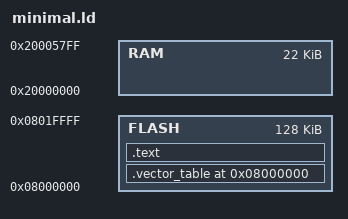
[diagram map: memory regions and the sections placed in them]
MEMORY
{
  FLASH : ORIGIN = 0x08000000, LENGTH = 128K
  RAM : ORIGIN = 0x20000000, LENGTH = 22K
}

ENTRY(Reset)

SECTIONS
{
  .vector_table 0x08000000 :
  {
    LONG(0x20005800);
    LONG(Reset + 1);
  } > FLASH

  .text :
  {
    *(.text*)
    *(.rodata*)
  } > FLASH

  /DISCARD/ :
  {
    *(.ARM.exidx*)
    *(.note.gnu.build-id*)
  }
}
